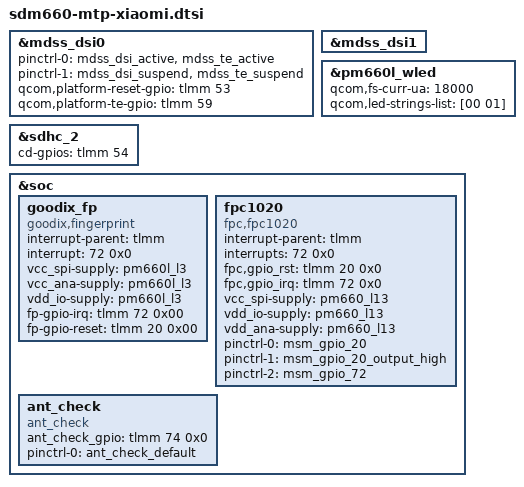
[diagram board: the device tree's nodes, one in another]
#include "sdm660-novatek-i2c_d2s.dtsi"

&mdss_dsi0 {
	pinctrl-names = "mdss_default", "mdss_sleep";
	pinctrl-0 = <&mdss_dsi_active &mdss_te_active>;
	pinctrl-1 = <&mdss_dsi_suspend &mdss_te_suspend>;
	qcom,platform-reset-gpio = <&tlmm 53 0>;
	qcom,platform-te-gpio = <&tlmm 59 0>;
};

&mdss_dsi1 {
	/delete-property/ qcom,dsi-pref-prim-pan;
	/delete-property/ pinctrl-names;
	/delete-property/ pinctrl-0;
	/delete-property/ pinctrl-1;
	/delete-property/ qcom,platform-reset-gpio;
	/delete-property/ qcom,platform-te-gpio;
};

&pm660l_wled {
	qcom,fs-curr-ua = <18000>;
	qcom,led-strings-list = [00 01];
};

&sdhc_2 {
	cd-gpios = <&tlmm 54 0x0>;
};

&soc {
	goodix_fp {
		compatible = "goodix,fingerprint";
		interrupt-parent = <&tlmm>;
		interrupt = <72 0x0>;
		vcc_spi-supply = <&pm660l_l3>;
		vcc_ana-supply = <&pm660l_l3>;
		vdd_io-supply = <&pm660l_l3>;
		fp-gpio-irq = <&tlmm 72 0x00>;
		fp-gpio-reset = <&tlmm 20 0x00>;
		status = "okay";
	};

	fpc1020 {
		status = "ok";
		compatible = "fpc,fpc1020";
		interrupt-parent = <&tlmm>;
		interrupts = <72 0x0>;
		fpc,gpio_rst    = <&tlmm 20 0x0>;
		fpc,gpio_irq    = <&tlmm 72 0x0>;
		vcc_spi-supply  = <&pm660_l13>;
		vdd_io-supply   = <&pm660_l13>;
		vdd_ana-supply  = <&pm660_l13>;

		pinctrl-names = "fpc1020_reset_reset",
			"fpc1020_reset_active",
			"fpc1020_irq_active";

		pinctrl-0 = <&msm_gpio_20>;
		pinctrl-1 = <&msm_gpio_20_output_high>;
		pinctrl-2 = <&msm_gpio_72>;
	};


	ant_check {
		compatible = "ant_check";
	        ant_check_gpio = <&tlmm 74 0x0>;
		pinctrl-names = "default";
		pinctrl-0 = <&ant_check_default>;
	};
};
